# cslr_i2c_001 register map
Vendor: Texas Instruments
Peripheral module from a debugger description file (folder C5505).
Address unit: 16 bits
Registers are 16-bit, access not given, reset 0x0 unless marked. A register's access mark holds for its fields unless they carry their own. Offsets are as the file gives them; lines under a group give offsets from that group; [hi:lo] are bit positions; {n}, {i} and the like mark numbered series; 'fields as' and 'values as' point back to an identical list; <NAME> marks a mode.

## I2C — The I2C peripheral provides an interface between the DSP and other devices that are compliant with the I2C-bus specification and connected by way of an I2C-bus. External components that are attached to this two-wire serial bus can transmit and receive data that is up to eight bits wide both to and from the DSP through the I2C peripheral.
0x00 ICOAR — The I2C own address register (ICOAR) is used to specify its own slave address, which distinguishes it from other slaves connected to the I2C-bus. If the 7-bit addressing mode is selected (XA = 0 in ICMDR), only bits 6-0 are used; bits 9-7 are ignored.
  [9:0] OADDR rw — Own slave address. Provides the slave address of the I2C. In 7-bit addressing mode (XA = 0 in ICMDR): bits 6-0 provide the 7-bit slave address of the I2C. Bits 9-7 are ignored. In 10-bit addressing mode (XA = 1 in ICMDR): bits 9-0 provide the 10-bit slave address of the I2C.
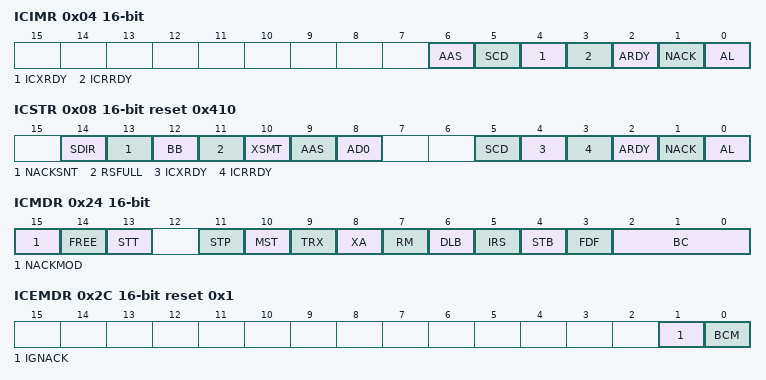
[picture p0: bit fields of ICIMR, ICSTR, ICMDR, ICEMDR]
0x04 ICIMR — The I2C interrupt mask register (ICIMR) is used to individually enable or disable I2C interrupt requests.
  [all] fields
    0=DISABLE (Interrupt request is disabled.); 1=ENABLE (Interrupt request is enabled.)
  [6] AAS rw — Address-as-slave interrupt enable bit.
  [5] SCD rw — Stop condition detected interrupt enable bit.
  [4] ICXRDY rw — Transmit-data-ready interrupt enable bit.
  [3] ICRRDY rw — Receive-data-ready interrupt enable bit.
  [2] ARDY rw — Register-access-ready interrupt enable bit.
  [1] NACK rw — No-acknowledgment interrupt enable bit.
  [0] AL rw — Arbitration-lost interrupt enable bit
0x08 ICSTR reset 0x410 — The I2C interrupt status register (ICSTR) is used to determine which interrupt has occurred and to read status information.
  [14] SDIR rw — Slave direction bit. In digital-loopback mode (DLB), the SDIR bit is cleared to 0. SDIR is cleared by one of the following events: - A STOP or a START condition. - SDIR is manually cleared. To clear this bit, write a 1 to it.
    0=CLEAR (I2C is acting as a master-transmitter/receiver or a slave-receiver.); 1=SET (I2C is acting as a slave-transmitter.)
  [13] NACKSNT rw — No-acknowledgment sent bit. NACKSNT bit is used when the I2C is in the receiver mode. One instance in which NACKSNT is affected is when the NACK mode is used (see the description for NACKMOD in Section 3.9). NACKSNT is cleared by one of the following events: - It is manually cleared. To clear this bit, write a 1 to it. - The I2C is reset (either when 0 is written to the IRS bit of ICMDR or when the processor is reset).
    0=CLEAR (NACK is not sent.); 1=SET (NACK is sent.)
  [12] BB rw — Bus busy bit. BB bit indicates whether the I2C-bus is busy or is free for another data transfer. In the master mode, BB is controlled by the software. BB is cleared by one of the following events: - The I2C receives or transmits a STOP bit (bus free). - BB is manually cleared. To clear this bit, write a 1 to it. - The I2C is reset (either when 0 is written to the IRS bit of ICMDR or when the processor is reset). BB is set by one of the following events: - The I2C has received or transmitted a START bit on the bus. - SCL is in a low state and the IRS bit in ICMDR is 0.
    0=CLEAR (Bus is free.); 1=SET (Bus is busy.)
  [11] RSFULL ro — Receive shift register full bit. RSFULL indicates an overrun condition during reception. Overrun occurs when the receive shift register (ICRSR) is full with new data but the previous data has not been read from the data receive register (ICDRR). The new data will not be copied to ICDRR until the previous data is read. As new bits arrive from the SDA pin, they overwrite the bits in ICRSR. RSFULL is cleared by one of the following events: - ICDRR is read. - The I2C is reset (either when 0 is written to the IRS bit of ICMDR or when the processor is reset).
    0=CLEAR (No overrun is detected.); 1=SET (Overrun is detected.)
  [10] XSMT ro — Transmit shift register empty bit. XSMT indicates that the transmitter has experienced underflow. Underflow occurs when the transmit shift register (ICXSR) is empty but the data transmit register (ICDXR) has not been loaded since the last ICDXR-to-ICXSR transfer. The next ICDXR-to-ICXSR transfer will not occur until new data is in ICDXR. If new data is not transferred in time, the previous data may be re-transmitted on the SDA pin. XSMT is set by one of the following events: - Data is written to ICDXR. - The I2C is reset (either when 0 is written to the IRS bit of ICMDR or when the processor is reset).
    0=CLEAR (Underflow is detected.); 1=SET (No underflow is detected.)
  [9] AAS ro — Addressed-as-slave bit.
    0=CLEAR (The AAS bit has been cleared by a repeated START condition or by a STOP condition.); 1=SET (AAS is set by one of the following events: - I2C has recognized its own slave address or an address of all zeros (general call). - The first data word has been received in the free data format (FDF = 1 in ICMDR).)
  [8] AD0 ro — Address 0 bit.
    0=CLEAR (AD0 has been cleared by a START or STOP condition.); 1=SET (An address of all zeros (general call) is detected.)
  [5] SCD rw — Stop condition detected bit. SCD indicates when a STOP condition has been detected on the I2C bus. The STOP condition could be generated by the I2C or by another I2C device connected to the bus. SCD is cleared by one of the following events: - By reading the INTCODE bits in ICIVR as 110b. - SCD is manually cleared. To clear this bit, write a 1 to it.
    0=CLEAR (No STOP condition has been detected.); 1=SET (A STOP condition has been detected.)
  [4] ICXRDY rw — Transmit-data-ready interrupt flag bit. ICXRDY indicates that the data transmit register (ICDXR) is ready to accept new data because the previous data has been copied from ICDXR to the transmit shift register (ICXSR). The CPU can poll ICXRDY or use the XRDY interrupt request. ICXRDY is cleared by one of the following events: - Data is written to ICDXR. - ICXRDY is manually cleared. To clear this bit, write a 1 to it.
    0=CLEAR (ICDXR is not ready.); 1=SET (ICDXR is ready. Data has been copied from ICDXR to ICXSR. ICXRDY is forced to 1 when the I2C is reset.)
  [3] ICRRDY rw — Receive-data-ready interrupt flag bit. ICRRDY indicates that the data receive register (ICDRR) is ready to be read because data has been copied from the receive shift register (ICRSR) to ICDRR. The CPU can poll ICRRDY or use the RRDY interrupt request. 0 ICDRR is not ready. ICRRDY is cleared by one of the following events: ICDRR is read. ICRRDY is manually cleared. To clear this bit, write a 1 to it. The I2C is reset (either when 0 is written to the IRS bit of ICMDR or when the processor is reset). 1 ICDRR is ready. Data has been copied from ICRSR to ICDRR.
    0=CLEAR (ICDRR is not ready.); 1=SET (ICDRR is ready. Data has been copied from ICRSR to ICDRR.)
  [2] ARDY rw — Register-access-ready interrupt flag bit (only applicable when the I2C is in the master mode). ARDY indicates that the I2C registers are ready to be accessed because the previously programmed address, data, and command values have been used. The CPU can poll ARDY or use the ARDY interrupt request. ARDY is cleared by one of the following events: - The I2C starts using the current register contents. - ARDY is manually cleared. To clear this bit, write a 1 to it. - The I2C is reset (either when 0 is written to the IRS bit of ICMDR or when the processor is reset). This bit is set after the slave address appears on the I2C bus. - In the nonrepeat mode (RM = 0 in ICMDR): If STP = 0 in ICMDR, ARDY is set when the internal data counter counts down to 0. If STP = 1, ARDY is not affected (instead, the I2C generates a STOP condition when the counter reaches 0). - In the repeat mode (RM = 1): ARDY is set at the end of each data word transmitted from ICDXR.
    0=CLEAR (The registers are not ready to be accessed.); 1=SET (The registers are ready to be accessed.)
  [1] NACK rw — No-acknowledgment interrupt flag bit. NACK applies when the I2C is a transmitter (master or slave). NACK indicates whether the I2C has detected an acknowledge bit (ACK) or a no-acknowledge bit (NACK) from the receiver. The CPU can poll NACK or use the NACK interrupt request. NACK is cleared by one of the following events: - An acknowledge bit (ACK) has been sent by the receiver. - NACK is manually cleared. To clear this bit, write a 1 to it. - The CPU reads the interrupt source register (ICISR) when the register contains the code for a NACK interrupt. - The I2C is reset (either when 0 is written to the IRS bit of ICMDR or when the processor is reset). Note: While the I2C performs a general call transfer, NACK is 1, even if one or more slaves send acknowledgment.
    0=CLEAR (ACK received/NACK is not received.); 1=SET (NACK bit is received.)
  [0] AL rw — Arbitration-lost interrupt flag bit (only applicable when the I2C is a master-transmitter). AL primarily indicates when the I2C has lost an arbitration contest with another master-transmitter. The CPU can poll AL or use the AL interrupt request. AL is cleared by one of the following events: - AL is manually cleared. To clear this bit, write a 1 to it. - The CPU reads the interrupt source register (ICISR) when the register contains the code for an AL interrupt. - The I2C is reset (either when 0 is written to the IRS bit of ICMDR or when the processor is reset). AL is set by one of the following events: - The I2C senses that it has lost an arbitration with two or more competing transmitters that started a transmission almost simultaneously. - The I2C attempts to start a transfer while the BB (bus busy) bit is set to 1. When AL is set to 1, the MST and STP bits of ICMDR are cleared, and the I2C becomes a slave-receiver.
    0=CLEAR (Arbitration is not lost.); 1=SET (Arbitration is lost.)
0x0C ICCLKL rw — For each I2C serial clock cycle, ICCL determines the amount of time the signal is low. ICCLKL must be configured while the I2C is still in reset (IRS = 0 in ICMDR).
  [15:0] ICCL — Clock low-time divide-down value of 1-65536. The period of the module clock is multiplied by (ICCL + d) to produce the low-time duration of the I2C serial on the SCL pin.
0x10 ICCLKH rw — For each I2C serial clock cycle, ICCH determines the amount of time the signal is high. ICCLKH must be configured while the I2C is still in reset (IRS = 0 in ICMDR).
  [15:0] ICCH — Clock high-time divide-down value of 1-65536. The period of the module clock is multiplied by (ICCH + d) to produce the high-time duration of the I2C serial on the SCL pin.
0x14 ICCNT rw — The I2C data count register (ICCNT) is used to indicate how many data words to transfer when the I2C is configured as a master-transmitter (MST = 1 and TRX = 1 in ICMDR) and the repeat mode is off (RM = 0 in ICMDR). In the repeat mode (RM = 1), ICCNT is not used.
  [15:0] ICDC — Data count value. When RM = 0 in ICMDR, ICDC indicates the number of data words to transfer in the nonrepeat mode. When RM = 1 in ICMDR, the value in ICCNT is a don't care. If STP = 1 in ICMDR, a STOP condition is generated when the internal data counter counts down to 0. When ICDC = 0, the start value loaded to the internal data counter is 65536.
0x18 ICDRR — The I2C data receive register (ICDRR) is used to read the receive data.
  [7:0] D ro — Receive data.
0x1C ICSAR reset 0x3FF — The I2C slave address register (ICSAR) contains a 7-bit or 10-bit slave address.
  [9:0] SADDR rw — Slave address. Provides the slave address that the I2C transmits when it is in master-transmitter mode. In 7-bit addressing mode (XA = 0 in ICMDR): bits 6-0 provide the 7-bit slave address that the I2C transmits when it is in the master-transmitter mode. Bits 9-7 are ignored. In 10-bit addressing mode (XA = 1 in ICMDR): Bits 9-0 provide the 10-bit slave address that the I2C transmits when it is in the master-transmitter mode.
0x20 ICDXR — The CPU or DMA writes transmit data to the I2C data transmit register (ICDXR).
  [7:0] D rw — Transmit data.
0x24 ICMDR — The I2C mode register (ICMDR) contains the control bits of the I2C.
  [15] NACKMOD rw — No-acknowledge (NACK) mode bit (only applicable when the I2C is a receiver).
    0=CLEAR (In slave-receiver mode: The I2C sends an acknowledge (ACK) bit to the transmitter during the each acknowledge cycle on the bus. The I2C only sends a no-acknowledge (NACK) bit if you set the NACKMOD bit. In master-receiver mode: The I2C sends an ACK bit during each acknowledge cycle until the internal data counter counts down to 0. When the counter reaches 0, the I2C sends a NACK bit to the transmitter. To have a NACK bit sent earlier, you must set the NACKMOD bit.); 1=SET (In either slave-receiver or master-receiver mode: The I2C sends a NACK bit to the transmitter during the next acknowledge cycle on the bus. Once the NACK bit has been sent, NACKMOD is cleared. To send a NACK bit in the next acknowledge cycle, you must set NACKMOD before the rising edge of the last data bit.)
  [14] FREE rw — This emulation mode bit is used to determine the state of the I2C when a breakpoint is encountered in the high-level language debugger.
    0=CLEAR (When I2C is master: If SCL is low when the breakpoint occurs, the I2C stops immediately and keeps driving SCL low, whether the I2C is the transmitter or the receiver. If SCL is high, the I2C waits until SCL becomes low and then stops. When I2C is slave: A breakpoint forces the I2C to stop when the current transmission/reception is complete.); 1=SET (The I2C runs free; that is, it continues to operate when a breakpoint occurs.)
  [13] STT rw — START condition bit (only applicable when the I2C is a master). The RM, STT, and STP bits determine when the I2C starts and stops data transmissions. Note that the STT and STP bits can be used to terminate the repeat mode.
    0=CLEAR (In master mode, STT is automatically cleared after the START condition has been generated. In slave mode, if STT is 0, the I2C does not monitor the bus for commands from a master. As a result, the I2C performs no data transfers.); 1=SET (In master mode, setting STT to 1 causes the I2C to generate a START condition on the I2C-bus. In slave mode, if STT is 1, the I2C monitors the bus and transmits/receives data in response to commands from a master.)
  [11] STP rw — STOP condition bit (only applicable when the I2C is a master). The RM, STT, and STP bits determine when the I2C starts and stops data transmissions. Note that the STT and STP bits can be used to terminate the repeat mode.
    0=CLEAR (STP is automatically cleared after the STOP condition has been generated.); 1=SET (STP has been set to generate a STOP condition when the internal data counter of the I2C counts down to 0.)
  [10] MST rw — Master mode bit. MST determines whether the I2C is in the slave mode or the master mode. MST is automatically changed from 1 to 0 when the I2C master generates a STOP condition.
    0=CLEAR (Slave mode. The I2C is a slave and receives the serial clock from the master.); 1=SET (Master mode. The I2C is a master and generates the serial clock on the SCL pin.)
  [9] TRX rw — Transmitter mode bit. When relevant, TRX selects whether the I2C is in the transmitter mode or the receiver mode.
    0=CLEAR (Receiver mode. The I2C is a receiver and receives data on the SDA pin.); 1=SET (Transmitter mode. The I2C is a transmitter and transmits data on the SDA pin.)
  [8] XA rw — Expanded address enable bit.
    0=CLEAR (7-bit addressing mode (normal address mode). The I2C transmits 7-bit slave addresses (from bits 6-0 of ICSAR), and its own slave address has 7 bits (bits 6-0 of ICOAR).); 1=SET (10-bit addressing mode (expanded address mode). The I2C transmits 10-bit slave addresses (from bits 9-0 of ICSAR), and its own slave address has 10 bits (bits 9-0 of ICOAR).)
  [7] RM rw — Repeat mode bit (only applicable when the I2C is a master-transmitter). The RM, STT, and STP bits determine when the I2C starts and stops data transmissions. If the I2C is configured in slave mode, the RM bit is don't care.
    0=CLEAR (Nonrepeat mode. The value in the data count register (ICCNT) determines how many data words are received/transmitted by the I2C.); 1=SET (Repeat mode. Data words are continuously received/transmitted by the I2C until the STP bit is manually set to 1.)
  [6] DLB rw — Digital loopback mode bit (only applicable when the I2C is a master-transmitter). This bit disables or enables the digital loopback mode of the I2C. Note that DLB mode in the free data format mode (DLB = 1 and FDF = 1) is not supported.
    0=CLEAR (Digital loopback mode is disabled.); 1=SET (Digital loopback mode is enabled. In this mode, the MST bit must be set to 1 and data transmitted out of ICDXR is received in ICDRR after n clock cycles by an internal path, where: n = ((I2C input clock frequency/prescaled module clock frequency) ´ 8) The transmit clock is also the receive clock. The address transmitted on the SDA pin is the address in ICOAR.)
  [5] IRS rw — I2C reset bit. Note that if IRS is reset during a transfer, it can cause the I2C bus to hang (SDA and SCL are in a high-impedance state).
    0=CLEAR (The I2C is in reset/disabled. When this bit is cleared to 0, all status bits (in ICSTR) are set to their default values.); 1=SET (The I2C is enabled.)
  [4] STB rw — START byte mode bit (only applicable when the I2C is a master). As described in version 2.1 of the Philips I2C-bus specification, the START byte can be used to help a slave that needs extra time to detect a START condition. When the I2C is a slave, the I2C ignores a START byte from a master, regardless of the value of the STB bit.
    0=CLEAR (The I2C is not in the START byte mode.); 1=SET (The I2C is in the START byte mode. When you set the START condition bit (STT), the I2C begins the transfer with more than just a START condition. Specifically, it generates: 1. A START condition 2. A START byte (0000 0001b) 3. A dummy acknowledge clock pulse 4. A repeated START condition The I2C sends the slave address that is in ICSAR.)
  [3] FDF rw — Free data format mode bit. Note that DLB mode in the free data format mode (DLB = 1 and FDF = 1) is not supported.
    0=CLEAR (Free data format mode is disabled. Transfers use the 7-/10-bit addressing format selected by the XA bit.); 1=SET (Free data format mode is enabled.)
  [2:0] BC rw — Bit count bits. BC defines the number of bits (2 to 8) in the next data word that is to be received or transmitted by the I2C. The number of bits selected with BC must match the data size of the other device. Note that when BC = 0, a data word has 8 bits.
    0=8BITS (8 bits per data word); 1=RSV (Reserved); {v}={v}BITS ({v} bits per data word) (v=2..7)
0x28 ICIVR — The I2C interrupt vector register (ICIVR) is used by the CPU to determine which event generated the I2C interrupt.
  [2:0] INTCODE ro — Interrupt code. The binary-coded-interrupt vector indicates which interrupt has occurred. Reading the ICIVR clears the interrupt flag; if other interrupts are pending, a new interrupt is generated. If there are more than one interrupt flag, reading the ICIVR clears the highest priority interrupt flag. Note that users must read (clear) the IVR before doing another start otherwise the IVR could contain incorrect (old interrupt flags) value.
    0=NONE (No interrupt occurred); 1=AL (Arbitration-lost interrupt (AL)); 2=NACK (No-acknowledgment interrupt (NACK)); 3=ARDY (Register-access-ready interrupt (ARDY)); 4=RDR (Receive-data-ready interrupt (ICRRDY)); 5=TDR (Transmit-data-ready interrupt (ICXRDY)); 6=SCD (Stop condition detected interrupt (SCD)); 7=AAS (Address-as-slave interrupt (AAS))
0x2C ICEMDR reset 0x1 — The I2C extended mode register (ICEMDR) is used to indicate which condition generates a transmit data ready interrupt.
  [1] IGNACK rw — Ignore NACK mode.
    0=CLEAR (Master transmitter operates normally, that is, it discontinues the data transfer and sets the ARDY and NACK bits in ICSTR when receiving a NACK from the slave.); 1=SET (Master transmitter ignores a NACK from the slave.)
  [0] BCM rw — Backward compatibility mode bit. Determines which condition generates a transmit data ready interrupt. The BCM bit only has an effect when the I2C is operating as a slave-transmitter.
    0=CLEAR (The transmit data ready interrupt is generated when the master requests more data by sending an acknowledge signal after the transmission of the last data.); 1=SET (The transmit data ready interrupt is generated when the data in ICDXR is copied to ICXSR.)
0x30 ICPSC — The I2C prescaler register (ICPSC) is used for dividing down the I2C input clock to obtain the desired prescaled module clock for the operation of the I2C.
  [7:0] IPSC rw — I2C prescaler divide-down value. IPSC determines how much the I2C input clock is divided to create the I2C prescaled module clock: I2C clock frequency = I2C input clock frequency/(IPSC + 1) Note: IPSC must be initialized while the I2C is in reset (IRS = 0 in ICMDR).
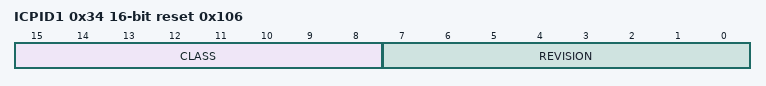
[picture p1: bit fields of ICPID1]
0x34 ICPID1 ro reset 0x106 — The I2C peripheral identification registers (ICPID1) contain identification data (class, revision, and type) for the peripheral.
  [15:8] CLASS — Identifies class of peripheral.
  [7:0] REVISION — Identifies revision of peripheral.
0x38 ICPID2 reset 0x5 — The I2C peripheral identification register (ICPID2).
  [7:0] TYPE ro — Identifies type of peripheral.
